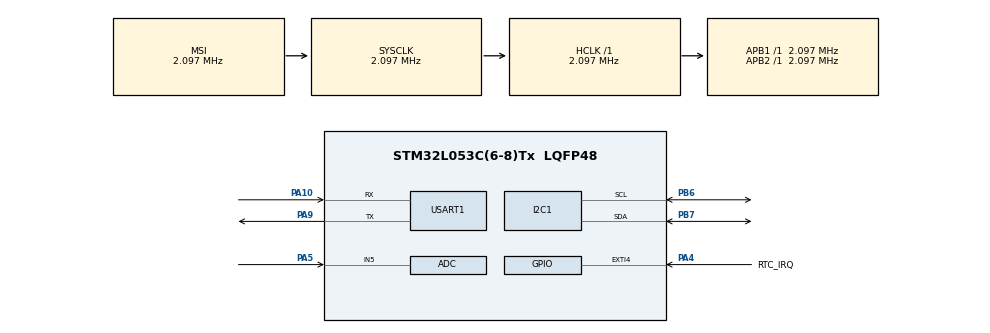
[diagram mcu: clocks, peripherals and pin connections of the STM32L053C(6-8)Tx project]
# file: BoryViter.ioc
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Dma.Request0=USART1_RX
Dma.USART1_RX.0.Direction=DMA_PERIPH_TO_MEMORY
Dma.USART1_RX.0.Instance=DMA1_Channel3
Dma.USART1_RX.0.MemDataAlignment=DMA_MDATAALIGN_BYTE
Dma.USART1_RX.0.MemInc=DMA_MINC_ENABLE
Dma.USART1_RX.0.Mode=DMA_CIRCULAR
Dma.USART1_RX.0.PeriphDataAlignment=DMA_PDATAALIGN_BYTE
Dma.USART1_RX.0.PeriphInc=DMA_PINC_DISABLE
Dma.USART1_RX.0.Priority=DMA_PRIORITY_LOW
Mcu.Family=STM32L0
Mcu.Name=STM32L053C(6-8)Tx
Mcu.Package=LQFP48
NVIC.DMA1_Channel2_3_IRQn=true\:0\:0\:false\:false\:true\:false\:true\:true
NVIC.EXTI4_15_IRQn=true\:0\:0\:false\:false\:true\:true\:true\:true
PA10.Mode=Asynchronous
PA10.Signal=USART1_RX
PA13.Mode=Serial_Wire
PA13.Signal=SYS_SWDIO
PA14.Mode=Serial_Wire
PA14.Signal=SYS_SWCLK
PA4.GPIO_Label=RTC_IRQ
PA4.GPIO_ModeDefaultEXTI=GPIO_MODE_IT_FALLING
PA4.GPIO_PuPd=GPIO_PULLUP
PA4.Signal=GPXTI4
PA5.Mode=IN5
PA5.Signal=ADC_IN5
PA9.Mode=Asynchronous
PA9.Signal=USART1_TX
PB6.GPIO_Pu=GPIO_PULLUP
PB6.Mode=I2C
PB6.Signal=I2C1_SCL
PB7.GPIO_Pu=GPIO_PULLUP
PB7.Mode=I2C
PB7.Signal=I2C1_SDA
ProjectManager.HeapSize=0x200
ProjectManager.StackSize=0x400
ProjectManager.TargetToolchain=STM32CubeIDE
RCC.AHBFreq_Value=2097000
RCC.APB1Freq_Value=2097000
RCC.APB1TimFreq_Value=2097000
RCC.APB2Freq_Value=2097000
RCC.APB2TimFreq_Value=2097000
RCC.HSE_VALUE=8000000
RCC.HSI16_VALUE=16000000
RCC.HSI48_VALUE=48000000
RCC.HSI_VALUE=16000000
RCC.LSE_VALUE=32768
RCC.MSI_VALUE=2097000
RCC.SYSCLKFreq_VALUE=2097000
RCC.VCOOutputFreq_Value=48000000
RTC.Alarm-Alarm\ A=RTC_ALARM_A
USART1.VirtualMode-Asynchronous=VM_ASYNC
VP_RNG_VS_RNG.Mode=RNG_Activate
VP_RTC_VS_RTC_Activate.Mode=RTC_Enabled
VP_RTC_VS_RTC_Alarm_A_Intern.Mode=Alarm A
VP_RTC_VS_RTC_Calendar.Mode=RTC_Calendar
board=custom

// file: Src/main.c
/* USER CODE BEGIN Header */
/**
  ******************************************************************************
  * @file           : main.c
  * @brief          : Main program body
  ******************************************************************************
  * @attention
  *
  * <h2><center>&copy; Copyright (c) 2020 STMicroelectronics.
  * All rights reserved.</center></h2>
  *
  * This software component is licensed by ST under BSD 3-Clause license,
  * the "License"; You may not use this file except in compliance with the
  * License. You may obtain a copy of the License at:
  *                        opensource.org/licenses/BSD-3-Clause
  *
  ******************************************************************************
  */
/* USER CODE END Header */
#include "main.h"
#include "adc.h"
#include "dma.h"
#include "i2c.h"
#include "rng.h"
#include "rtc.h"
#include "usart.h"
#include "gpio.h"

/* USER CODE BEGIN Includes */

	#include "boryviter_sm.h"

/* USER CODE END Includes */

void SystemClock_Config(void);

int main(void)
{

  /* MCU Configuration--------------------------------------------------------*/

  /* Reset of all peripherals, Initializes the Flash interface and the Systick. */
  HAL_Init();

  /* Configure the system clock */
  SystemClock_Config();

  /* Initialize all configured peripherals */
  MX_GPIO_Init();
  MX_DMA_Init();
  MX_USART1_UART_Init();
  MX_ADC_Init();
  MX_I2C1_Init();
  MX_RTC_Init();
  MX_RNG_Init();
  /* USER CODE BEGIN 2 */

  	  	  BoryViter_Init();

  /* USER CODE END 2 */

  /* Infinite loop */
  /* USER CODE BEGIN WHILE */
  while (1)
  {
	  	  BoryViter_Main();

    /* USER CODE END WHILE */

  }
}

void SystemClock_Config(void)
{
  RCC_OscInitTypeDef RCC_OscInitStruct = {0};
  RCC_ClkInitTypeDef RCC_ClkInitStruct = {0};
  RCC_PeriphCLKInitTypeDef PeriphClkInit = {0};

  /** Configure the main internal regulator output voltage
  */
  __HAL_PWR_VOLTAGESCALING_CONFIG(PWR_REGULATOR_VOLTAGE_SCALE1);

  /** Initializes the RCC Oscillators according to the specified parameters
  * in the RCC_OscInitTypeDef structure.
  */
  RCC_OscInitStruct.OscillatorType = RCC_OSCILLATORTYPE_HSI|RCC_OSCILLATORTYPE_LSI
                              |RCC_OSCILLATORTYPE_MSI;
  RCC_OscInitStruct.HSIState = RCC_HSI_ON;
  RCC_OscInitStruct.HSICalibrationValue = RCC_HSICALIBRATION_DEFAULT;
  RCC_OscInitStruct.LSIState = RCC_LSI_ON;
  RCC_OscInitStruct.MSIState = RCC_MSI_ON;
  RCC_OscInitStruct.MSICalibrationValue = 0;
  RCC_OscInitStruct.MSIClockRange = RCC_MSIRANGE_5;
  RCC_OscInitStruct.PLL.PLLState = RCC_PLL_ON;
  RCC_OscInitStruct.PLL.PLLSource = RCC_PLLSOURCE_HSI;
  RCC_OscInitStruct.PLL.PLLMUL = RCC_PLLMUL_3;
  RCC_OscInitStruct.PLL.PLLDIV = RCC_PLLDIV_2;
  if (HAL_RCC_OscConfig(&RCC_OscInitStruct) != HAL_OK)
  {
    Error_Handler();
  }

  /** Initializes the CPU, AHB and APB buses clocks
  */
  RCC_ClkInitStruct.ClockType = RCC_CLOCKTYPE_HCLK|RCC_CLOCKTYPE_SYSCLK
                              |RCC_CLOCKTYPE_PCLK1|RCC_CLOCKTYPE_PCLK2;
  RCC_ClkInitStruct.SYSCLKSource = RCC_SYSCLKSOURCE_MSI;
  RCC_ClkInitStruct.AHBCLKDivider = RCC_SYSCLK_DIV1;
  RCC_ClkInitStruct.APB1CLKDivider = RCC_HCLK_DIV1;
  RCC_ClkInitStruct.APB2CLKDivider = RCC_HCLK_DIV1;

  if (HAL_RCC_ClockConfig(&RCC_ClkInitStruct, FLASH_LATENCY_0) != HAL_OK)
  {
    Error_Handler();
  }
  PeriphClkInit.PeriphClockSelection = RCC_PERIPHCLK_USART1|RCC_PERIPHCLK_I2C1
                              |RCC_PERIPHCLK_RTC|RCC_PERIPHCLK_USB;
  PeriphClkInit.Usart1ClockSelection = RCC_USART1CLKSOURCE_PCLK2;
  PeriphClkInit.I2c1ClockSelection = RCC_I2C1CLKSOURCE_PCLK1;
  PeriphClkInit.RTCClockSelection = RCC_RTCCLKSOURCE_LSI;
  PeriphClkInit.UsbClockSelection = RCC_USBCLKSOURCE_PLL;
  if (HAL_RCCEx_PeriphCLKConfig(&PeriphClkInit) != HAL_OK)
  {
    Error_Handler();
  }
}

void Error_Handler(void)
{
}
